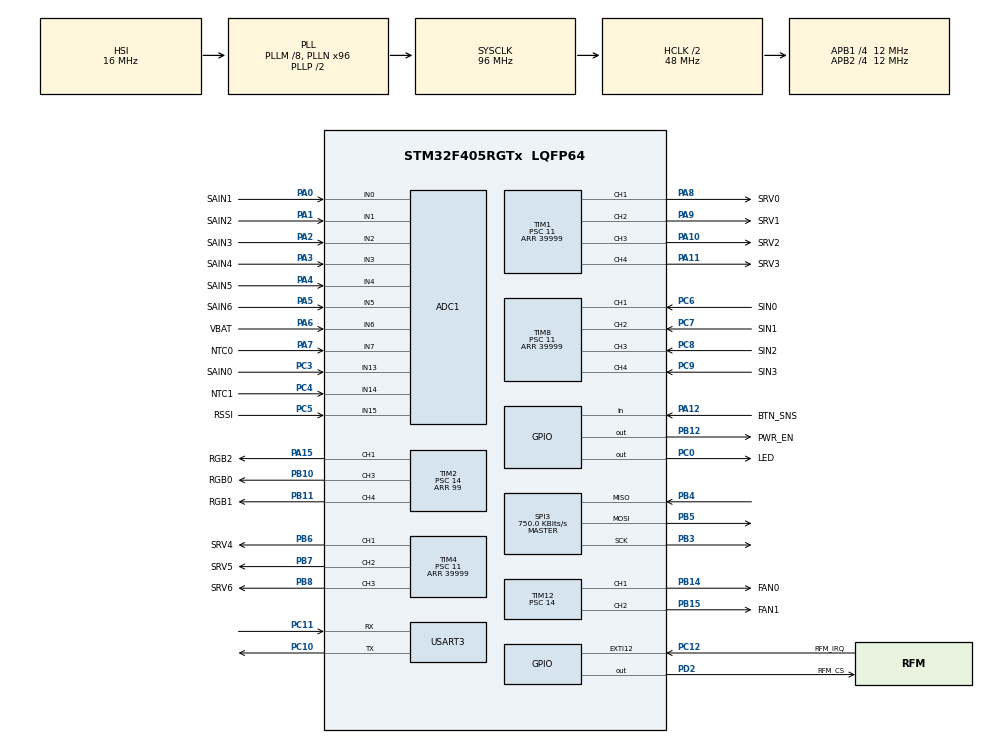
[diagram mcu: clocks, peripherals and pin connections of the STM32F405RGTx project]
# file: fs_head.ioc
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ADC1.Channel-0\#ChannelRegularConversion=ADC_CHANNEL_13
ADC1.Channel-1\#ChannelRegularConversion=ADC_CHANNEL_0
ADC1.Channel-2\#ChannelRegularConversion=ADC_CHANNEL_1
ADC1.Channel-3\#ChannelRegularConversion=ADC_CHANNEL_2
ADC1.Channel-4\#ChannelRegularConversion=ADC_CHANNEL_3
ADC1.Channel-5\#ChannelRegularConversion=ADC_CHANNEL_4
ADC1.Channel-6\#ChannelRegularConversion=ADC_CHANNEL_6
ADC1.Channel-7\#ChannelRegularConversion=ADC_CHANNEL_14
ADC1.Channel-8\#ChannelRegularConversion=ADC_CHANNEL_15
ADC1.DMAContinuousRequests=ENABLE
ADC1.EOCSelection=ADC_EOC_SEQ_CONV
ADC1.ExternalTrigConv=ADC_EXTERNALTRIGCONV_T3_TRGO
ADC1.NbrOfConversion=9
ADC1.NbrOfConversionFlag=1
ADC1.Rank-0\#ChannelRegularConversion=1
ADC1.Rank-1\#ChannelRegularConversion=2
ADC1.Rank-2\#ChannelRegularConversion=3
ADC1.Rank-3\#ChannelRegularConversion=4
ADC1.Rank-4\#ChannelRegularConversion=5
ADC1.Rank-5\#ChannelRegularConversion=6
ADC1.Rank-6\#ChannelRegularConversion=7
ADC1.Rank-7\#ChannelRegularConversion=8
ADC1.Rank-8\#ChannelRegularConversion=9
ADC1.SamplingTime-0\#ChannelRegularConversion=ADC_SAMPLETIME_15CYCLES
ADC1.SamplingTime-1\#ChannelRegularConversion=ADC_SAMPLETIME_15CYCLES
ADC1.SamplingTime-2\#ChannelRegularConversion=ADC_SAMPLETIME_15CYCLES
ADC1.SamplingTime-3\#ChannelRegularConversion=ADC_SAMPLETIME_15CYCLES
ADC1.SamplingTime-4\#ChannelRegularConversion=ADC_SAMPLETIME_15CYCLES
ADC1.SamplingTime-5\#ChannelRegularConversion=ADC_SAMPLETIME_3CYCLES
ADC1.SamplingTime-6\#ChannelRegularConversion=ADC_SAMPLETIME_15CYCLES
ADC1.SamplingTime-7\#ChannelRegularConversion=ADC_SAMPLETIME_15CYCLES
ADC1.SamplingTime-8\#ChannelRegularConversion=ADC_SAMPLETIME_15CYCLES
ADC1.ScanConvMode=ENABLE
ADC1.master=1
Dma.ADC1.0.Direction=DMA_PERIPH_TO_MEMORY
Dma.ADC1.0.FIFOMode=DMA_FIFOMODE_DISABLE
Dma.ADC1.0.Instance=DMA2_Stream0
Dma.ADC1.0.MemDataAlignment=DMA_MDATAALIGN_HALFWORD
Dma.ADC1.0.MemInc=DMA_MINC_ENABLE
Dma.ADC1.0.Mode=DMA_CIRCULAR
Dma.ADC1.0.PeriphDataAlignment=DMA_PDATAALIGN_HALFWORD
Dma.ADC1.0.PeriphInc=DMA_PINC_DISABLE
Dma.ADC1.0.Priority=DMA_PRIORITY_LOW
Dma.Request0=ADC1
Mcu.Family=STM32F4
Mcu.Name=STM32F405RGTx
Mcu.Package=LQFP64
NVIC.DMA2_Stream0_IRQn=true\:0\:0\:false\:false\:true\:false\:true
NVIC.EXTI15_10_IRQn=true\:0\:0\:false\:false\:true\:true\:true
NVIC.PriorityGroup=NVIC_PRIORITYGROUP_4
NVIC.USART3_IRQn=true\:0\:0\:false\:false\:true\:true\:true
PA0-WKUP.GPIO_Label=SAIN1
PA0-WKUP.Signal=ADCx_IN0
PA1.GPIO_Label=SAIN2
PA1.Signal=ADCx_IN1
PA10.GPIO_Label=SRV2
PA10.Signal=S_TIM1_CH3
PA11.GPIO_Label=SRV3
PA11.Signal=S_TIM1_CH4
PA12.GPIO_Label=BTN_SNS
PA12.Signal=GPIO_Input
PA13.Mode=Serial_Wire
PA13.Signal=SYS_JTMS-SWDIO
PA14.Mode=Serial_Wire
PA14.Signal=SYS_JTCK-SWCLK
PA15.GPIO_Label=RGB2
PA15.Signal=S_TIM2_CH1_ETR
PA2.GPIO_Label=SAIN3
PA2.Signal=ADCx_IN2
PA3.GPIO_Label=SAIN4
PA3.Signal=ADCx_IN3
PA4.GPIO_Label=SAIN5
PA4.Signal=ADCx_IN4
PA5.GPIO_Label=SAIN6
PA5.Signal=ADCx_IN5
PA6.GPIO_Label=VBAT
PA6.Signal=ADCx_IN6
PA7.GPIO_Label=NTC0
PA7.Signal=ADCx_IN7
PA8.GPIO_Label=SRV0
PA8.Signal=S_TIM1_CH1
PA9.GPIO_Label=SRV1
PA9.Signal=S_TIM1_CH2
PB10.GPIO_Label=RGB0
PB10.Signal=S_TIM2_CH3
PB11.GPIO_Label=RGB1
PB11.Signal=S_TIM2_CH4
PB12.GPIO_Label=PWR_EN
PB12.Signal=GPIO_Output
PB14.GPIO_Label=FAN0
PB14.Signal=S_TIM12_CH1
PB15.GPIO_Label=FAN1
PB15.Signal=S_TIM12_CH2
PB3.Mode=Full_Duplex_Master
PB3.Signal=SPI3_SCK
PB4.Mode=Full_Duplex_Master
PB4.Signal=SPI3_MISO
PB5.Mode=Full_Duplex_Master
PB5.Signal=SPI3_MOSI
PB6.GPIO_Label=SRV4
PB6.Signal=S_TIM4_CH1
PB7.GPIO_Label=SRV5
PB7.Signal=S_TIM4_CH2
PB8.GPIO_Label=SRV6
PB8.Signal=S_TIM4_CH3
PC0.GPIO_Label=LED
PC0.PinState=GPIO_PIN_SET
PC0.Signal=GPIO_Output
PC10.Mode=Asynchronous
PC10.Signal=USART3_TX
PC11.Mode=Asynchronous
PC11.Signal=USART3_RX
PC12.GPIO_Label=RFM_IRQ
PC12.GPIO_ModeDefaultEXTI=GPIO_MODE_IT_FALLING
PC12.Signal=GPXTI12
PC3.GPIO_Label=SAIN0
PC3.Signal=ADCx_IN13
PC4.GPIO_Label=NTC1
PC4.Signal=ADCx_IN14
PC5.GPIO_Label=RSSI
PC5.Signal=ADCx_IN15
PC6.GPIO_Label=SIN0
PC6.Signal=S_TIM8_CH1
PC7.GPIO_Label=SIN1
PC7.Signal=S_TIM8_CH2
PC8.GPIO_Label=SIN2
PC8.Signal=S_TIM8_CH3
PC9.GPIO_Label=SIN3
PC9.Signal=S_TIM8_CH4
PD2.GPIO_Label=RFM_CS
PD2.PinState=GPIO_PIN_SET
PD2.Signal=GPIO_Output
ProjectManager.HeapSize=0x200
ProjectManager.StackSize=0x400
ProjectManager.TargetToolchain=Makefile
RCC.48MHZClocksFreq_Value=48000000
RCC.AHBCLKDivider=RCC_SYSCLK_DIV2
RCC.AHBFreq_Value=48000000
RCC.APB1CLKDivider=RCC_HCLK_DIV4
RCC.APB1Freq_Value=12000000
RCC.APB1TimFreq_Value=24000000
RCC.APB2CLKDivider=RCC_HCLK_DIV4
RCC.APB2Freq_Value=12000000
RCC.APB2TimFreq_Value=24000000
RCC.CortexFreq_Value=48000000
RCC.HCLKFreq_Value=48000000
RCC.HSE_VALUE=25000000
RCC.HSI_VALUE=16000000
RCC.LSE_VALUE=32768
RCC.PLLM=8
RCC.PLLN=96
RCC.SYSCLKFreq_VALUE=96000000
RCC.SYSCLKSource=RCC_SYSCLKSOURCE_PLLCLK
RCC.VCOOutputFreq_Value=192000000
SH.ADCx_IN0.0=ADC1_IN0,IN0
SH.ADCx_IN1.0=ADC1_IN1,IN1
SH.ADCx_IN13.0=ADC1_IN13,IN13
SH.ADCx_IN14.0=ADC1_IN14,IN14
SH.ADCx_IN15.0=ADC1_IN15,IN15
SH.ADCx_IN2.0=ADC1_IN2,IN2
SH.ADCx_IN3.0=ADC1_IN3,IN3
SH.ADCx_IN4.0=ADC1_IN4,IN4
SH.ADCx_IN5.0=ADC1_IN5,IN5
SH.ADCx_IN6.0=ADC1_IN6,IN6
SH.ADCx_IN7.0=ADC1_IN7,IN7
SH.S_TIM12_CH1.0=TIM12_CH1,PWM Generation1 CH1
SH.S_TIM12_CH2.0=TIM12_CH2,PWM Generation2 CH2
SH.S_TIM1_CH1.0=TIM1_CH1,PWM Generation1 CH1
SH.S_TIM1_CH2.0=TIM1_CH2,PWM Generation2 CH2
SH.S_TIM1_CH3.0=TIM1_CH3,PWM Generation3 CH3
SH.S_TIM1_CH4.0=TIM1_CH4,PWM Generation4 CH4
SH.S_TIM2_CH1_ETR.0=TIM2_CH1,PWM Generation1 CH1
SH.S_TIM2_CH3.0=TIM2_CH3,PWM Generation3 CH3
SH.S_TIM2_CH4.0=TIM2_CH4,PWM Generation4 CH4
SH.S_TIM4_CH1.0=TIM4_CH1,PWM Generation1 CH1
SH.S_TIM4_CH2.0=TIM4_CH2,PWM Generation2 CH2
SH.S_TIM4_CH3.0=TIM4_CH3,PWM Generation3 CH3
SH.S_TIM8_CH1.0=TIM8_CH1,Input_Capture1_from_TI1
SH.S_TIM8_CH2.0=TIM8_CH2,Input_Capture2_from_TI2
SH.S_TIM8_CH3.0=TIM8_CH3,Input_Capture3_from_TI3
SH.S_TIM8_CH4.0=TIM8_CH4,Input_Capture4_from_TI4
SPI3.BaudRatePrescaler=SPI_BAUDRATEPRESCALER_16
SPI3.CalculateBaudRate=750.0 KBits/s
SPI3.DataSize=SPI_DATASIZE_8BIT
SPI3.Direction=SPI_DIRECTION_2LINES
SPI3.Mode=SPI_MODE_MASTER
SPI3.VirtualType=VM_MASTER
TIM1.AutoReloadPreload=TIM_AUTORELOAD_PRELOAD_ENABLE
TIM1.Channel-PWM\ Generation1\ CH1=TIM_CHANNEL_1
TIM1.Channel-PWM\ Generation2\ CH2=TIM_CHANNEL_2
TIM1.Channel-PWM\ Generation3\ CH3=TIM_CHANNEL_3
TIM1.Channel-PWM\ Generation4\ CH4=TIM_CHANNEL_4
TIM1.OCFastMode_PWM-PWM\ Generation1\ CH1=TIM_OCFAST_ENABLE
TIM1.OCFastMode_PWM-PWM\ Generation2\ CH2=TIM_OCFAST_ENABLE
TIM1.OCFastMode_PWM-PWM\ Generation3\ CH3=TIM_OCFAST_ENABLE
TIM1.OCFastMode_PWM-PWM\ Generation4\ CH4=TIM_OCFAST_ENABLE
TIM1.Period=39999
TIM1.Prescaler=11
TIM1.Pulse-PWM\ Generation1\ CH1=0
TIM1.Pulse-PWM\ Generation2\ CH2=0
TIM1.Pulse-PWM\ Generation3\ CH3=0
TIM1.Pulse-PWM\ Generation4\ CH4=0
TIM12.AutoReloadPreload=TIM_AUTORELOAD_PRELOAD_ENABLE
TIM12.Channel-PWM\ Generation1\ CH1=TIM_CHANNEL_1
TIM12.Channel-PWM\ Generation2\ CH2=TIM_CHANNEL_2
TIM12.OCFastMode_PWM-PWM\ Generation1\ CH1=TIM_OCFAST_ENABLE
TIM12.OCFastMode_PWM-PWM\ Generation2\ CH2=TIM_OCFAST_ENABLE
TIM12.Period=99
TIM12.Prescaler=14
TIM12.Pulse-PWM\ Generation1\ CH1=0
TIM12.Pulse-PWM\ Generation2\ CH2=0
TIM2.AutoReloadPreload=TIM_AUTORELOAD_PRELOAD_ENABLE
TIM2.Channel-PWM\ Generation1\ CH1=TIM_CHANNEL_1
TIM2.Channel-PWM\ Generation3\ CH3=TIM_CHANNEL_3
TIM2.Channel-PWM\ Generation4\ CH4=TIM_CHANNEL_4
TIM2.OCFastMode_PWM-PWM\ Generation1\ CH1=TIM_OCFAST_ENABLE
TIM2.OCFastMode_PWM-PWM\ Generation3\ CH3=TIM_OCFAST_ENABLE
TIM2.OCFastMode_PWM-PWM\ Generation4\ CH4=TIM_OCFAST_ENABLE
TIM2.Period=99
TIM2.Prescaler=14
TIM2.Pulse-PWM\ Generation1\ CH1=0
TIM2.Pulse-PWM\ Generation3\ CH3=0
TIM2.Pulse-PWM\ Generation4\ CH4=0
TIM3.AutoReloadPreload=TIM_AUTORELOAD_PRELOAD_ENABLE
TIM3.Period=999
TIM3.Prescaler=11
TIM3.TIM_MasterOutputTrigger=TIM_TRGO_UPDATE
TIM4.AutoReloadPreload=TIM_AUTORELOAD_PRELOAD_ENABLE
TIM4.Channel-PWM\ Generation1\ CH1=TIM_CHANNEL_1
TIM4.Channel-PWM\ Generation2\ CH2=TIM_CHANNEL_2
TIM4.Channel-PWM\ Generation3\ CH3=TIM_CHANNEL_3
TIM4.OCFastMode_PWM-PWM\ Generation1\ CH1=TIM_OCFAST_ENABLE
TIM4.OCFastMode_PWM-PWM\ Generation2\ CH2=TIM_OCFAST_ENABLE
TIM4.OCFastMode_PWM-PWM\ Generation3\ CH3=TIM_OCFAST_ENABLE
TIM4.Period=39999
TIM4.Prescaler=11
TIM4.Pulse-PWM\ Generation1\ CH1=0
TIM4.Pulse-PWM\ Generation2\ CH2=0
TIM4.Pulse-PWM\ Generation3\ CH3=0
TIM8.AutoReloadPreload=TIM_AUTORELOAD_PRELOAD_ENABLE
TIM8.Channel-Input_Capture1_from_TI1=TIM_CHANNEL_1
TIM8.Channel-Input_Capture2_from_TI2=TIM_CHANNEL_2
TIM8.Channel-Input_Capture3_from_TI3=TIM_CHANNEL_3
TIM8.Channel-Input_Capture4_from_TI4=TIM_CHANNEL_4
TIM8.Period=39999
TIM8.Prescaler=11
USART3.VirtualMode=VM_ASYNC
VP_CRC_VS_CRC.Mode=CRC_Activate
VP_RNG_VS_RNG.Mode=RNG_Activate
VP_TIM3_VS_ClockSourceINT.Mode=Internal
board=custom

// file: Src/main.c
/* USER CODE BEGIN Header */
/**
  ******************************************************************************
  * @file           : main.c
  * @brief          : Main program body
  ******************************************************************************
  * @attention
  *
  * <h2><center>&copy; Copyright (c) 2019 STMicroelectronics.
  * All rights reserved.</center></h2>
  *
  * This software component is licensed by ST under BSD 3-Clause license,
  * the "License"; You may not use this file except in compliance with the
  * License. You may obtain a copy of the License at:
  *                        opensource.org/licenses/BSD-3-Clause
  *
  ******************************************************************************
  */
/* USER CODE END Header */

#include "main.h"

/* USER CODE BEGIN Includes */
#include "flash_regions.h"
/* USER CODE END Includes */

/* USER CODE BEGIN PD */
void init(void);
void loop(void);
/* USER CODE END PD */

ADC_HandleTypeDef hadc1;
DMA_HandleTypeDef hdma_adc1;

CRC_HandleTypeDef hcrc;

RNG_HandleTypeDef hrng;

SPI_HandleTypeDef hspi3;

TIM_HandleTypeDef htim1;
TIM_HandleTypeDef htim2;
TIM_HandleTypeDef htim3;
TIM_HandleTypeDef htim4;
TIM_HandleTypeDef htim8;
TIM_HandleTypeDef htim12;

UART_HandleTypeDef huart3;

void SystemClock_Config(void);
static void MX_GPIO_Init(void);
static void MX_DMA_Init(void);
static void MX_ADC1_Init(void);
static void MX_CRC_Init(void);
static void MX_RNG_Init(void);
static void MX_SPI3_Init(void);
static void MX_TIM1_Init(void);
static void MX_TIM2_Init(void);
static void MX_TIM4_Init(void);
static void MX_TIM8_Init(void);
static void MX_TIM12_Init(void);
static void MX_USART3_UART_Init(void);
static void MX_TIM3_Init(void);

int main(void)
{
  /* USER CODE BEGIN 1 */
    SCB->VTOR = ADDR_APP;
    __enable_irq();
  /* USER CODE END 1 */

  /* MCU Configuration--------------------------------------------------------*/

  /* Reset of all peripherals, Initializes the Flash interface and the Systick. */
  HAL_Init();

  /* Configure the system clock */
  SystemClock_Config();

  /* Initialize all configured peripherals */
  MX_GPIO_Init();
  MX_DMA_Init();
  MX_ADC1_Init();
  MX_CRC_Init();
  MX_RNG_Init();
  MX_SPI3_Init();
  MX_TIM1_Init();
  MX_TIM2_Init();
  MX_TIM4_Init();
  MX_TIM8_Init();
  MX_TIM12_Init();
  MX_USART3_UART_Init();
  MX_TIM3_Init();
  /* USER CODE BEGIN 2 */
init();
  /* USER CODE END 2 */

  /* Infinite loop */
  /* USER CODE BEGIN WHILE */
  while (1)
  {
      loop();
    /* USER CODE END WHILE */

  }
}

void SystemClock_Config(void)
{
  RCC_OscInitTypeDef RCC_OscInitStruct = {0};
  RCC_ClkInitTypeDef RCC_ClkInitStruct = {0};

  /** Configure the main internal regulator output voltage
  */
  __HAL_RCC_PWR_CLK_ENABLE();
  __HAL_PWR_VOLTAGESCALING_CONFIG(PWR_REGULATOR_VOLTAGE_SCALE1);
  /** Initializes the CPU, AHB and APB busses clocks
  */
  RCC_OscInitStruct.OscillatorType = RCC_OSCILLATORTYPE_HSI;
  RCC_OscInitStruct.HSIState = RCC_HSI_ON;
  RCC_OscInitStruct.HSICalibrationValue = RCC_HSICALIBRATION_DEFAULT;
  RCC_OscInitStruct.PLL.PLLState = RCC_PLL_ON;
  RCC_OscInitStruct.PLL.PLLSource = RCC_PLLSOURCE_HSI;
  RCC_OscInitStruct.PLL.PLLM = 8;
  RCC_OscInitStruct.PLL.PLLN = 96;
  RCC_OscInitStruct.PLL.PLLP = RCC_PLLP_DIV2;
  RCC_OscInitStruct.PLL.PLLQ = 4;
  if (HAL_RCC_OscConfig(&RCC_OscInitStruct) != HAL_OK)
  {
    Error_Handler();
  }
  /** Initializes the CPU, AHB and APB busses clocks
  */
  RCC_ClkInitStruct.ClockType = RCC_CLOCKTYPE_HCLK|RCC_CLOCKTYPE_SYSCLK
                              |RCC_CLOCKTYPE_PCLK1|RCC_CLOCKTYPE_PCLK2;
  RCC_ClkInitStruct.SYSCLKSource = RCC_SYSCLKSOURCE_PLLCLK;
  RCC_ClkInitStruct.AHBCLKDivider = RCC_SYSCLK_DIV2;
  RCC_ClkInitStruct.APB1CLKDivider = RCC_HCLK_DIV4;
  RCC_ClkInitStruct.APB2CLKDivider = RCC_HCLK_DIV4;

  if (HAL_RCC_ClockConfig(&RCC_ClkInitStruct, FLASH_LATENCY_1) != HAL_OK)
  {
    Error_Handler();
  }
}

static void MX_ADC1_Init(void)
{

  ADC_ChannelConfTypeDef sConfig = {0};

  /** Configure the global features of the ADC (Clock, Resolution, Data Alignment and number of conversion)
  */
  hadc1.Instance = ADC1;
  hadc1.Init.ClockPrescaler = ADC_CLOCK_SYNC_PCLK_DIV2;
  hadc1.Init.Resolution = ADC_RESOLUTION_12B;
  hadc1.Init.ScanConvMode = ENABLE;
  hadc1.Init.ContinuousConvMode = DISABLE;
  hadc1.Init.DiscontinuousConvMode = DISABLE;
  hadc1.Init.ExternalTrigConvEdge = ADC_EXTERNALTRIGCONVEDGE_RISING;
  hadc1.Init.ExternalTrigConv = ADC_EXTERNALTRIGCONV_T3_TRGO;
  hadc1.Init.DataAlign = ADC_DATAALIGN_RIGHT;
  hadc1.Init.NbrOfConversion = 9;
  hadc1.Init.DMAContinuousRequests = ENABLE;
  hadc1.Init.EOCSelection = ADC_EOC_SEQ_CONV;
  if (HAL_ADC_Init(&hadc1) != HAL_OK)
  {
    Error_Handler();
  }
  /** Configure for the selected ADC regular channel its corresponding rank in the sequencer and its sample time.
  */
  sConfig.Channel = ADC_CHANNEL_13;
  sConfig.Rank = 1;
  sConfig.SamplingTime = ADC_SAMPLETIME_15CYCLES;
  if (HAL_ADC_ConfigChannel(&hadc1, &sConfig) != HAL_OK)
  {
    Error_Handler();
  }
  /** Configure for the selected ADC regular channel its corresponding rank in the sequencer and its sample time.
  */
  sConfig.Channel = ADC_CHANNEL_0;
  sConfig.Rank = 2;
  if (HAL_ADC_ConfigChannel(&hadc1, &sConfig) != HAL_OK)
  {
    Error_Handler();
  }
  /** Configure for the selected ADC regular channel its corresponding rank in the sequencer and its sample time.
  */
  sConfig.Channel = ADC_CHANNEL_1;
  sConfig.Rank = 3;
  if (HAL_ADC_ConfigChannel(&hadc1, &sConfig) != HAL_OK)
  {
    Error_Handler();
  }
  /** Configure for the selected ADC regular channel its corresponding rank in the sequencer and its sample time.
  */
  sConfig.Channel = ADC_CHANNEL_2;
  sConfig.Rank = 4;
  if (HAL_ADC_ConfigChannel(&hadc1, &sConfig) != HAL_OK)
  {
    Error_Handler();
  }
  /** Configure for the selected ADC regular channel its corresponding rank in the sequencer and its sample time.
  */
  sConfig.Channel = ADC_CHANNEL_3;
  sConfig.Rank = 5;
  if (HAL_ADC_ConfigChannel(&hadc1, &sConfig) != HAL_OK)
  {
    Error_Handler();
  }
  /** Configure for the selected ADC regular channel its corresponding rank in the sequencer and its sample time.
  */
  sConfig.Channel = ADC_CHANNEL_4;
  sConfig.Rank = 6;
  sConfig.SamplingTime = ADC_SAMPLETIME_3CYCLES;
  if (HAL_ADC_ConfigChannel(&hadc1, &sConfig) != HAL_OK)
  {
    Error_Handler();
  }
  /** Configure for the selected ADC regular channel its corresponding rank in the sequencer and its sample time.
  */
  sConfig.Channel = ADC_CHANNEL_6;
  sConfig.Rank = 7;
  sConfig.SamplingTime = ADC_SAMPLETIME_15CYCLES;
  if (HAL_ADC_ConfigChannel(&hadc1, &sConfig) != HAL_OK)
  {
    Error_Handler();
  }
  /** Configure for the selected ADC regular channel its corresponding rank in the sequencer and its sample time.
  */
  sConfig.Channel = ADC_CHANNEL_14;
  sConfig.Rank = 8;
  if (HAL_ADC_ConfigChannel(&hadc1, &sConfig) != HAL_OK)
  {
    Error_Handler();
  }
  /** Configure for the selected ADC regular channel its corresponding rank in the sequencer and its sample time.
  */
  sConfig.Channel = ADC_CHANNEL_15;
  sConfig.Rank = 9;
  if (HAL_ADC_ConfigChannel(&hadc1, &sConfig) != HAL_OK)
  {
    Error_Handler();
  }

}

static void MX_CRC_Init(void)
{

  hcrc.Instance = CRC;
  if (HAL_CRC_Init(&hcrc) != HAL_OK)
  {
    Error_Handler();
  }

}

static void MX_RNG_Init(void)
{

  hrng.Instance = RNG;
  if (HAL_RNG_Init(&hrng) != HAL_OK)
  {
    Error_Handler();
  }

}

static void MX_SPI3_Init(void)
{

  /* SPI3 parameter configuration*/
  hspi3.Instance = SPI3;
  hspi3.Init.Mode = SPI_MODE_MASTER;
  hspi3.Init.Direction = SPI_DIRECTION_2LINES;
  hspi3.Init.DataSize = SPI_DATASIZE_8BIT;
  hspi3.Init.CLKPolarity = SPI_POLARITY_LOW;
  hspi3.Init.CLKPhase = SPI_PHASE_1EDGE;
  hspi3.Init.NSS = SPI_NSS_SOFT;
  hspi3.Init.BaudRatePrescaler = SPI_BAUDRATEPRESCALER_16;
  hspi3.Init.FirstBit = SPI_FIRSTBIT_MSB;
  hspi3.Init.TIMode = SPI_TIMODE_DISABLE;
  hspi3.Init.CRCCalculation = SPI_CRCCALCULATION_DISABLE;
  hspi3.Init.CRCPolynomial = 10;
  if (HAL_SPI_Init(&hspi3) != HAL_OK)
  {
    Error_Handler();
  }

}

static void MX_TIM1_Init(void)
{

  TIM_MasterConfigTypeDef sMasterConfig = {0};
  TIM_OC_InitTypeDef sConfigOC = {0};
  TIM_BreakDeadTimeConfigTypeDef sBreakDeadTimeConfig = {0};

  htim1.Instance = TIM1;
  htim1.Init.Prescaler = 11;
  htim1.Init.CounterMode = TIM_COUNTERMODE_UP;
  htim1.Init.Period = 39999;
  htim1.Init.ClockDivision = TIM_CLOCKDIVISION_DIV1;
  htim1.Init.RepetitionCounter = 0;
  htim1.Init.AutoReloadPreload = TIM_AUTORELOAD_PRELOAD_ENABLE;
  if (HAL_TIM_PWM_Init(&htim1) != HAL_OK)
  {
    Error_Handler();
  }
  sMasterConfig.MasterOutputTrigger = TIM_TRGO_RESET;
  sMasterConfig.MasterSlaveMode = TIM_MASTERSLAVEMODE_DISABLE;
  if (HAL_TIMEx_MasterConfigSynchronization(&htim1, &sMasterConfig) != HAL_OK)
  {
    Error_Handler();
  }
  sConfigOC.OCMode = TIM_OCMODE_PWM1;
  sConfigOC.Pulse = 0;
  sConfigOC.OCPolarity = TIM_OCPOLARITY_HIGH;
  sConfigOC.OCNPolarity = TIM_OCNPOLARITY_HIGH;
  sConfigOC.OCFastMode = TIM_OCFAST_ENABLE;
  sConfigOC.OCIdleState = TIM_OCIDLESTATE_RESET;
  sConfigOC.OCNIdleState = TIM_OCNIDLESTATE_RESET;
  if (HAL_TIM_PWM_ConfigChannel(&htim1, &sConfigOC, TIM_CHANNEL_1) != HAL_OK)
  {
    Error_Handler();
  }
  if (HAL_TIM_PWM_ConfigChannel(&htim1, &sConfigOC, TIM_CHANNEL_2) != HAL_OK)
  {
    Error_Handler();
  }
  if (HAL_TIM_PWM_ConfigChannel(&htim1, &sConfigOC, TIM_CHANNEL_3) != HAL_OK)
  {
    Error_Handler();
  }
  if (HAL_TIM_PWM_ConfigChannel(&htim1, &sConfigOC, TIM_CHANNEL_4) != HAL_OK)
  {
    Error_Handler();
  }
  sBreakDeadTimeConfig.OffStateRunMode = TIM_OSSR_DISABLE;
  sBreakDeadTimeConfig.OffStateIDLEMode = TIM_OSSI_DISABLE;
  sBreakDeadTimeConfig.LockLevel = TIM_LOCKLEVEL_OFF;
  sBreakDeadTimeConfig.DeadTime = 0;
  sBreakDeadTimeConfig.BreakState = TIM_BREAK_DISABLE;
  sBreakDeadTimeConfig.BreakPolarity = TIM_BREAKPOLARITY_HIGH;
  sBreakDeadTimeConfig.AutomaticOutput = TIM_AUTOMATICOUTPUT_DISABLE;
  if (HAL_TIMEx_ConfigBreakDeadTime(&htim1, &sBreakDeadTimeConfig) != HAL_OK)
  {
    Error_Handler();
  }
  HAL_TIM_MspPostInit(&htim1);

}

static void MX_TIM2_Init(void)
{

  TIM_MasterConfigTypeDef sMasterConfig = {0};
  TIM_OC_InitTypeDef sConfigOC = {0};

  htim2.Instance = TIM2;
  htim2.Init.Prescaler = 14;
  htim2.Init.CounterMode = TIM_COUNTERMODE_UP;
  htim2.Init.Period = 99;
  htim2.Init.ClockDivision = TIM_CLOCKDIVISION_DIV1;
  htim2.Init.AutoReloadPreload = TIM_AUTORELOAD_PRELOAD_ENABLE;
  if (HAL_TIM_PWM_Init(&htim2) != HAL_OK)
  {
    Error_Handler();
  }
  sMasterConfig.MasterOutputTrigger = TIM_TRGO_RESET;
  sMasterConfig.MasterSlaveMode = TIM_MASTERSLAVEMODE_DISABLE;
  if (HAL_TIMEx_MasterConfigSynchronization(&htim2, &sMasterConfig) != HAL_OK)
  {
    Error_Handler();
  }
  sConfigOC.OCMode = TIM_OCMODE_PWM1;
  sConfigOC.Pulse = 0;
  sConfigOC.OCPolarity = TIM_OCPOLARITY_HIGH;
  sConfigOC.OCFastMode = TIM_OCFAST_ENABLE;
  if (HAL_TIM_PWM_ConfigChannel(&htim2, &sConfigOC, TIM_CHANNEL_1) != HAL_OK)
  {
    Error_Handler();
  }
  if (HAL_TIM_PWM_ConfigChannel(&htim2, &sConfigOC, TIM_CHANNEL_3) != HAL_OK)
  {
    Error_Handler();
  }
  if (HAL_TIM_PWM_ConfigChannel(&htim2, &sConfigOC, TIM_CHANNEL_4) != HAL_OK)
  {
    Error_Handler();
  }
  HAL_TIM_MspPostInit(&htim2);

}

static void MX_TIM3_Init(void)
{

  TIM_ClockConfigTypeDef sClockSourceConfig = {0};
  TIM_MasterConfigTypeDef sMasterConfig = {0};

  htim3.Instance = TIM3;
  htim3.Init.Prescaler = 11;
  htim3.Init.CounterMode = TIM_COUNTERMODE_UP;
  htim3.Init.Period = 999;
  htim3.Init.ClockDivision = TIM_CLOCKDIVISION_DIV1;
  htim3.Init.AutoReloadPreload = TIM_AUTORELOAD_PRELOAD_ENABLE;
  if (HAL_TIM_Base_Init(&htim3) != HAL_OK)
  {
    Error_Handler();
  }
  sClockSourceConfig.ClockSource = TIM_CLOCKSOURCE_INTERNAL;
  if (HAL_TIM_ConfigClockSource(&htim3, &sClockSourceConfig) != HAL_OK)
  {
    Error_Handler();
  }
  sMasterConfig.MasterOutputTrigger = TIM_TRGO_UPDATE;
  sMasterConfig.MasterSlaveMode = TIM_MASTERSLAVEMODE_DISABLE;
  if (HAL_TIMEx_MasterConfigSynchronization(&htim3, &sMasterConfig) != HAL_OK)
  {
    Error_Handler();
  }

}

static void MX_TIM4_Init(void)
{

  TIM_MasterConfigTypeDef sMasterConfig = {0};
  TIM_OC_InitTypeDef sConfigOC = {0};

  htim4.Instance = TIM4;
  htim4.Init.Prescaler = 11;
  htim4.Init.CounterMode = TIM_COUNTERMODE_UP;
  htim4.Init.Period = 39999;
  htim4.Init.ClockDivision = TIM_CLOCKDIVISION_DIV1;
  htim4.Init.AutoReloadPreload = TIM_AUTORELOAD_PRELOAD_ENABLE;
  if (HAL_TIM_PWM_Init(&htim4) != HAL_OK)
  {
    Error_Handler();
  }
  sMasterConfig.MasterOutputTrigger = TIM_TRGO_RESET;
  sMasterConfig.MasterSlaveMode = TIM_MASTERSLAVEMODE_DISABLE;
  if (HAL_TIMEx_MasterConfigSynchronization(&htim4, &sMasterConfig) != HAL_OK)
  {
    Error_Handler();
  }
  sConfigOC.OCMode = TIM_OCMODE_PWM1;
  sConfigOC.Pulse = 0;
  sConfigOC.OCPolarity = TIM_OCPOLARITY_HIGH;
  sConfigOC.OCFastMode = TIM_OCFAST_ENABLE;
  if (HAL_TIM_PWM_ConfigChannel(&htim4, &sConfigOC, TIM_CHANNEL_1) != HAL_OK)
  {
    Error_Handler();
  }
  if (HAL_TIM_PWM_ConfigChannel(&htim4, &sConfigOC, TIM_CHANNEL_2) != HAL_OK)
  {
    Error_Handler();
  }
  if (HAL_TIM_PWM_ConfigChannel(&htim4, &sConfigOC, TIM_CHANNEL_3) != HAL_OK)
  {
    Error_Handler();
  }
  HAL_TIM_MspPostInit(&htim4);

}

static void MX_TIM8_Init(void)
{

  TIM_MasterConfigTypeDef sMasterConfig = {0};
  TIM_IC_InitTypeDef sConfigIC = {0};

  htim8.Instance = TIM8;
  htim8.Init.Prescaler = 11;
  htim8.Init.CounterMode = TIM_COUNTERMODE_UP;
  htim8.Init.Period = 39999;
  htim8.Init.ClockDivision = TIM_CLOCKDIVISION_DIV1;
  htim8.Init.RepetitionCounter = 0;
  htim8.Init.AutoReloadPreload = TIM_AUTORELOAD_PRELOAD_ENABLE;
  if (HAL_TIM_IC_Init(&htim8) != HAL_OK)
  {
    Error_Handler();
  }
  sMasterConfig.MasterOutputTrigger = TIM_TRGO_RESET;
  sMasterConfig.MasterSlaveMode = TIM_MASTERSLAVEMODE_DISABLE;
  if (HAL_TIMEx_MasterConfigSynchronization(&htim8, &sMasterConfig) != HAL_OK)
  {
    Error_Handler();
  }
  sConfigIC.ICPolarity = TIM_INPUTCHANNELPOLARITY_RISING;
  sConfigIC.ICSelection = TIM_ICSELECTION_DIRECTTI;
  sConfigIC.ICPrescaler = TIM_ICPSC_DIV1;
  sConfigIC.ICFilter = 0;
  if (HAL_TIM_IC_ConfigChannel(&htim8, &sConfigIC, TIM_CHANNEL_1) != HAL_OK)
  {
    Error_Handler();
  }
  if (HAL_TIM_IC_ConfigChannel(&htim8, &sConfigIC, TIM_CHANNEL_2) != HAL_OK)
  {
    Error_Handler();
  }
  if (HAL_TIM_IC_ConfigChannel(&htim8, &sConfigIC, TIM_CHANNEL_3) != HAL_OK)
  {
    Error_Handler();
  }
  if (HAL_TIM_IC_ConfigChannel(&htim8, &sConfigIC, TIM_CHANNEL_4) != HAL_OK)
  {
    Error_Handler();
  }

}

static void MX_TIM12_Init(void)
{

  TIM_OC_InitTypeDef sConfigOC = {0};

  htim12.Instance = TIM12;
  htim12.Init.Prescaler = 14;
  htim12.Init.CounterMode = TIM_COUNTERMODE_UP;
  htim12.Init.Period = 99;
  htim12.Init.ClockDivision = TIM_CLOCKDIVISION_DIV1;
  htim12.Init.AutoReloadPreload = TIM_AUTORELOAD_PRELOAD_ENABLE;
  if (HAL_TIM_PWM_Init(&htim12) != HAL_OK)
  {
    Error_Handler();
  }
  sConfigOC.OCMode = TIM_OCMODE_PWM1;
  sConfigOC.Pulse = 0;
  sConfigOC.OCPolarity = TIM_OCPOLARITY_HIGH;
  sConfigOC.OCFastMode = TIM_OCFAST_ENABLE;
  if (HAL_TIM_PWM_ConfigChannel(&htim12, &sConfigOC, TIM_CHANNEL_1) != HAL_OK)
  {
    Error_Handler();
  }
  if (HAL_TIM_PWM_ConfigChannel(&htim12, &sConfigOC, TIM_CHANNEL_2) != HAL_OK)
  {
    Error_Handler();
  }
  HAL_TIM_MspPostInit(&htim12);

}

static void MX_USART3_UART_Init(void)
{

  huart3.Instance = USART3;
  huart3.Init.BaudRate = 115200;
  huart3.Init.WordLength = UART_WORDLENGTH_8B;
  huart3.Init.StopBits = UART_STOPBITS_1;
  huart3.Init.Parity = UART_PARITY_NONE;
  huart3.Init.Mode = UART_MODE_TX_RX;
  huart3.Init.HwFlowCtl = UART_HWCONTROL_NONE;
  huart3.Init.OverSampling = UART_OVERSAMPLING_16;
  if (HAL_UART_Init(&huart3) != HAL_OK)
  {
    Error_Handler();
  }

}

static void MX_DMA_Init(void)
{
  /* DMA controller clock enable */
  __HAL_RCC_DMA2_CLK_ENABLE();

  /* DMA interrupt init */
  /* DMA2_Stream0_IRQn interrupt configuration */
  HAL_NVIC_SetPriority(DMA2_Stream0_IRQn, 0, 0);
  HAL_NVIC_EnableIRQ(DMA2_Stream0_IRQn);

}

static void MX_GPIO_Init(void)
{
  GPIO_InitTypeDef GPIO_InitStruct = {0};

  /* GPIO Ports Clock Enable */
  __HAL_RCC_GPIOC_CLK_ENABLE();
  __HAL_RCC_GPIOA_CLK_ENABLE();
  __HAL_RCC_GPIOB_CLK_ENABLE();
  __HAL_RCC_GPIOD_CLK_ENABLE();

  /*Configure GPIO pin Output Level */
  HAL_GPIO_WritePin(LED_GPIO_Port, LED_Pin, GPIO_PIN_SET);

  /*Configure GPIO pin Output Level */
  HAL_GPIO_WritePin(PWR_EN_GPIO_Port, PWR_EN_Pin, GPIO_PIN_RESET);

  /*Configure GPIO pin Output Level */
  HAL_GPIO_WritePin(RFM_CS_GPIO_Port, RFM_CS_Pin, GPIO_PIN_SET);

  /*Configure GPIO pin : LED_Pin */
  GPIO_InitStruct.Pin = LED_Pin;
  GPIO_InitStruct.Mode = GPIO_MODE_OUTPUT_PP;
  GPIO_InitStruct.Pull = GPIO_NOPULL;
  GPIO_InitStruct.Speed = GPIO_SPEED_FREQ_LOW;
  HAL_GPIO_Init(LED_GPIO_Port, &GPIO_InitStruct);

  /*Configure GPIO pin : PWR_EN_Pin */
  GPIO_InitStruct.Pin = PWR_EN_Pin;
  GPIO_InitStruct.Mode = GPIO_MODE_OUTPUT_PP;
  GPIO_InitStruct.Pull = GPIO_NOPULL;
  GPIO_InitStruct.Speed = GPIO_SPEED_FREQ_LOW;
  HAL_GPIO_Init(PWR_EN_GPIO_Port, &GPIO_InitStruct);

  /*Configure GPIO pin : BTN_SNS_Pin */
  GPIO_InitStruct.Pin = BTN_SNS_Pin;
  GPIO_InitStruct.Mode = GPIO_MODE_INPUT;
  GPIO_InitStruct.Pull = GPIO_NOPULL;
  HAL_GPIO_Init(BTN_SNS_GPIO_Port, &GPIO_InitStruct);

  /*Configure GPIO pin : RFM_IRQ_Pin */
  GPIO_InitStruct.Pin = RFM_IRQ_Pin;
  GPIO_InitStruct.Mode = GPIO_MODE_IT_FALLING;
  GPIO_InitStruct.Pull = GPIO_NOPULL;
  HAL_GPIO_Init(RFM_IRQ_GPIO_Port, &GPIO_InitStruct);

  /*Configure GPIO pin : RFM_CS_Pin */
  GPIO_InitStruct.Pin = RFM_CS_Pin;
  GPIO_InitStruct.Mode = GPIO_MODE_OUTPUT_PP;
  GPIO_InitStruct.Pull = GPIO_NOPULL;
  GPIO_InitStruct.Speed = GPIO_SPEED_FREQ_LOW;
  HAL_GPIO_Init(RFM_CS_GPIO_Port, &GPIO_InitStruct);

  /* EXTI interrupt init*/
  HAL_NVIC_SetPriority(EXTI15_10_IRQn, 0, 0);
  HAL_NVIC_EnableIRQ(EXTI15_10_IRQn);

}

void Error_Handler(void)
{
}

/************************ (C) COPYRIGHT STMicroelectronics *****END OF FILE****/
